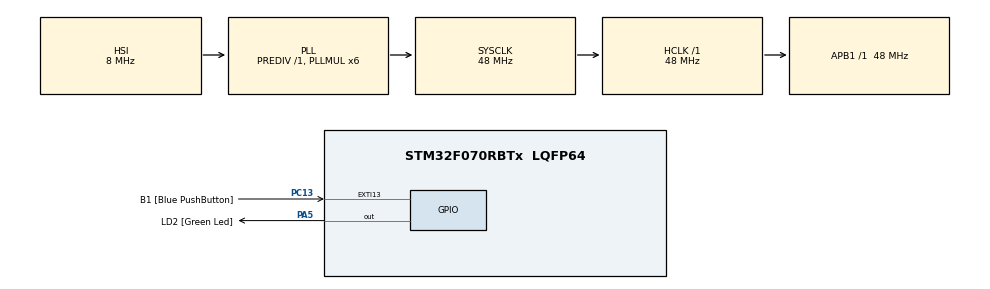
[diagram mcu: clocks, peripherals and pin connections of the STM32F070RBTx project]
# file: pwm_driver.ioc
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Mcu.Family=STM32F0
Mcu.Name=STM32F070RBTx
Mcu.Package=LQFP64
PA13.GPIO_Label=TMS
PA13.Signal=SYS_SWDIO
PA2.GPIO_Label=USART_TX
PA2.Signal=USART2_TX
PA3.GPIO_Label=USART_RX
PA3.Signal=USART2_RX
PA5.GPIO_Label=LD2 [Green Led]
PA5.Signal=GPIO_Output
PC13.GPIO_Label=B1 [Blue PushButton]
PC13.GPIO_ModeDefaultEXTI=GPIO_MODE_IT_FALLING
PC13.Signal=GPXTI13
PC14-OSC32_IN.GPIO_Label=RCC_OSC32_IN
PC14-OSC32_IN.Signal=RCC_OSC32_IN
PC15-OSC32_OUT.GPIO_Label=RCC_OSC32_OUT
PC15-OSC32_OUT.Signal=RCC_OSC32_OUT
PF0-OSC_IN.GPIO_Label=RCC_OSC_IN
PF0-OSC_IN.Signal=RCC_OSC_IN
PF1-OSC_OUT.GPIO_Label=RCC_OSC_OUT
PF1-OSC_OUT.Signal=RCC_OSC_OUT
ProjectManager.HeapSize=0x200
ProjectManager.StackSize=0x400
ProjectManager.TargetToolchain=STM32CubeIDE
RCC.AHBFreq_Value=48000000
RCC.APB1Freq_Value=48000000
RCC.APB1TimFreq_Value=48000000
RCC.HCLKFreq_Value=48000000
RCC.PLLMUL=RCC_PLL_MUL6
RCC.SYSCLKFreq_VALUE=48000000
RCC.SYSCLKSource=RCC_SYSCLKSOURCE_PLLCLK
board=NUCLEO-F070RB

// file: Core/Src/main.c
/* USER CODE BEGIN Header */
/**
  ******************************************************************************
  * @file           : main.c
  * @brief          : Main program body
  ******************************************************************************
  * @attention
  *
  * Copyright (c) 2023 STMicroelectronics.
  * All rights reserved.
  *
  * This software is licensed under terms that can be found in the LICENSE file
  * in the root directory of this software component.
  * If no LICENSE file comes with this software, it is provided AS-IS.
  *
  ******************************************************************************
  */
/* USER CODE END Header */
#include "main.h"
/* USER CODE BEGIN Includes */
#include "pwm.h"
/* USER CODE END Includes */

void SystemClock_Config(void);
static void MX_GPIO_Init(void);
/* USER CODE BEGIN PFP */
static void pwm_sweep(void);
static void pwm_sweep1(void);
/* USER CODE END PFP */

int main(void)
{

  /* MCU Configuration--------------------------------------------------------*/

  /* Reset of all peripherals, Initializes the Flash interface and the Systick. */
  HAL_Init();

  /* Configure the system clock */
  SystemClock_Config();

  /* Initialize all configured peripherals */
  //MX_GPIO_Init();
  /* USER CODE BEGIN 2 */
pwm_init();
  /* USER CODE END 2 */

  /* Infinite loop */
  /* USER CODE BEGIN WHILE */
pwm_enable();
  while (1)
  {
    /* USER CODE END WHILE */

    /* USER CODE BEGIN 3 */
	  //pwm_sweep1();
	  TIM3->CCR1 = 1;
	  	TIM3->CCR2 = 1;
  }
  /* USER CODE END 3 */
}

static void pwm_sweep(void){
	int32_t sweep=0;
	for(sweep=0; sweep<100; sweep++){
		pwm_set_duty_cycle(sweep,CHANNEL1);
		//pwm_set_duty_cycle(100-sweep,CHANNEL2);
		HAL_Delay(5);
	}
	for(sweep=100; sweep>0; sweep--){
			pwm_set_duty_cycle(sweep,CHANNEL1);
			//pwm_set_duty_cycle(100-sweep,CHANNEL2);
			HAL_Delay(5);
		}
}

static void pwm_sweep1(void){

	int32_t sweep=1;
	pwm_set_duty_cycle(sweep,CHANNEL1);
	pwm_set_duty_cycle(sweep,CHANNEL2);
}

void TIM3_IRQHandler(void){
	TIM3->SR &=~(TIM_SR_UIF);
	//TIM3->SR &=~(TIM_SR_CC1IF);
	//TIM3->SR &=~(TIM_SR_CC2IF);
	led_PC8();
	GPIOC->ODR ^=GPIO_PIN_8;
	//HAL_Delay(1500);
	//GPIOC->ODR &=~(GPIO_PIN_8);
}
void SystemClock_Config(void)
{
  RCC_OscInitTypeDef RCC_OscInitStruct = {0};
  RCC_ClkInitTypeDef RCC_ClkInitStruct = {0};

  /** Initializes the RCC Oscillators according to the specified parameters
  * in the RCC_OscInitTypeDef structure.
  */
  RCC_OscInitStruct.OscillatorType = RCC_OSCILLATORTYPE_HSI;
  RCC_OscInitStruct.HSIState = RCC_HSI_ON;
  RCC_OscInitStruct.HSICalibrationValue = RCC_HSICALIBRATION_DEFAULT;
  RCC_OscInitStruct.PLL.PLLState = RCC_PLL_ON;
  RCC_OscInitStruct.PLL.PLLSource = RCC_PLLSOURCE_HSI;
  RCC_OscInitStruct.PLL.PLLMUL = RCC_PLL_MUL6;
  RCC_OscInitStruct.PLL.PREDIV = RCC_PREDIV_DIV1;
  if (HAL_RCC_OscConfig(&RCC_OscInitStruct) != HAL_OK)
  {
    Error_Handler();
  }

  /** Initializes the CPU, AHB and APB buses clocks
  */
  RCC_ClkInitStruct.ClockType = RCC_CLOCKTYPE_HCLK|RCC_CLOCKTYPE_SYSCLK
                              |RCC_CLOCKTYPE_PCLK1;
  RCC_ClkInitStruct.SYSCLKSource = RCC_SYSCLKSOURCE_PLLCLK;
  RCC_ClkInitStruct.AHBCLKDivider = RCC_SYSCLK_DIV1;
  RCC_ClkInitStruct.APB1CLKDivider = RCC_HCLK_DIV1;

  if (HAL_RCC_ClockConfig(&RCC_ClkInitStruct, FLASH_LATENCY_1) != HAL_OK)
  {
    Error_Handler();
  }
}

static void MX_GPIO_Init(void)
{
  GPIO_InitTypeDef GPIO_InitStruct = {0};

  /* GPIO Ports Clock Enable */
  __HAL_RCC_GPIOC_CLK_ENABLE();
  __HAL_RCC_GPIOF_CLK_ENABLE();
  __HAL_RCC_GPIOA_CLK_ENABLE();

  /*Configure GPIO pin Output Level */
  HAL_GPIO_WritePin(LD2_GPIO_Port, LD2_Pin, GPIO_PIN_RESET);

  /*Configure GPIO pin : B1_Pin */
  GPIO_InitStruct.Pin = B1_Pin;
  GPIO_InitStruct.Mode = GPIO_MODE_IT_FALLING;
  GPIO_InitStruct.Pull = GPIO_NOPULL;
  HAL_GPIO_Init(B1_GPIO_Port, &GPIO_InitStruct);

  /*Configure GPIO pins : USART_TX_Pin USART_RX_Pin */
  GPIO_InitStruct.Pin = USART_TX_Pin|USART_RX_Pin;
  GPIO_InitStruct.Mode = GPIO_MODE_AF_PP;
  GPIO_InitStruct.Pull = GPIO_NOPULL;
  GPIO_InitStruct.Speed = GPIO_SPEED_FREQ_HIGH;
  GPIO_InitStruct.Alternate = GPIO_AF1_USART2;
  HAL_GPIO_Init(GPIOA, &GPIO_InitStruct);

  /*Configure GPIO pin : LD2_Pin */
  GPIO_InitStruct.Pin = LD2_Pin;
  GPIO_InitStruct.Mode = GPIO_MODE_OUTPUT_PP;
  GPIO_InitStruct.Pull = GPIO_NOPULL;
  GPIO_InitStruct.Speed = GPIO_SPEED_FREQ_LOW;
  HAL_GPIO_Init(LD2_GPIO_Port, &GPIO_InitStruct);

}

void Error_Handler(void)
{
  __disable_irq();
  while (1)
  {
  }
}
